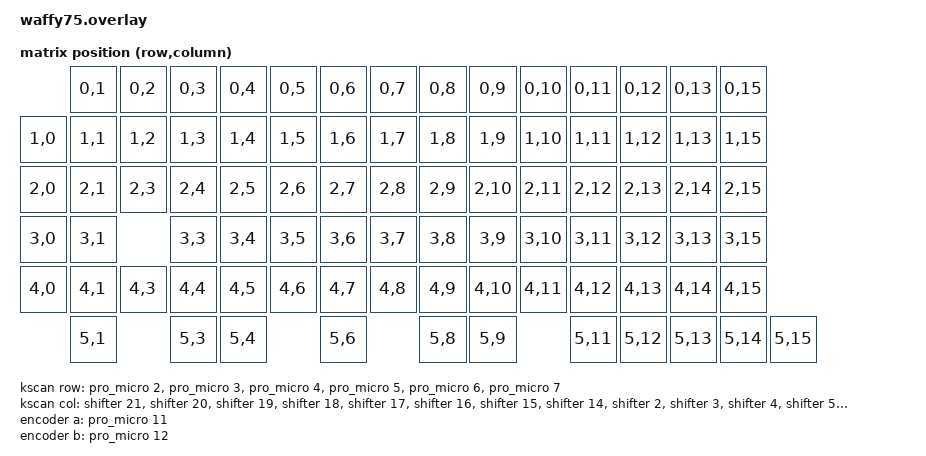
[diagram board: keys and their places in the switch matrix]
// This file was generated from a template. Edit it to match your keyboard.
// See https://zmk.dev/docs/development/hardware-integration/new-shield for more
// instructions.

#include <dt-bindings/zmk/matrix_transform.h>

#include "waffy75-layouts.dtsi"

&pro_micro_spi {
    status = "okay";
    cs-gpios = <&pro_micro 13 GPIO_ACTIVE_LOW>;
    shifter: 595@0 {
        compatible = "zmk,gpio-595";
        status = "okay";
        gpio-controller;
        spi-max-frequency = <200000>;
        reg = <0>;
        #gpio-cells = <2>;
        ngpios = <24>;
    };
};

/ {
    chosen {
        zmk,physical-layout = &default_layout;
    };

    kscan: kscan {
        // If the hardware does not use a switch matrix, change this to the
        // appropriate driver and update the properties below to match.
        // See https://zmk.dev/docs/config/kscan for supported key scan drivers.
        compatible = "zmk,kscan-gpio-matrix";
        // Set this to "col2row" or "row2col" to match the hardware. If using
        // "row2col", change the col-gpios to (GPIO_ACTIVE_HIGH | GPIO_PULL_DOWN)
        // and the row-gpios to GPIO_ACTIVE_HIGH.
        diode-direction = "col2row";
        wakeup-source;

        // Replace these comments with the GPIO pins in the matrix.
        // See https://zmk.dev/docs/development/hardware-integration/new-shield#shield-overlays
        col-gpios
            = <&shifter 21 GPIO_ACTIVE_HIGH>
            , <&shifter 20 GPIO_ACTIVE_HIGH>
            , <&shifter 19 GPIO_ACTIVE_HIGH>
            , <&shifter 18 GPIO_ACTIVE_HIGH>
            , <&shifter 17 GPIO_ACTIVE_HIGH>
            , <&shifter 16 GPIO_ACTIVE_HIGH>
            , <&shifter 15 GPIO_ACTIVE_HIGH>
            , <&shifter 14 GPIO_ACTIVE_HIGH>
            , <&shifter 2 GPIO_ACTIVE_HIGH>
            , <&shifter 3 GPIO_ACTIVE_HIGH>
            , <&shifter 4 GPIO_ACTIVE_HIGH>
            , <&shifter 5 GPIO_ACTIVE_HIGH>
            , <&shifter 6 GPIO_ACTIVE_HIGH>
            , <&shifter 7 GPIO_ACTIVE_HIGH>
            , <&shifter 8 GPIO_ACTIVE_HIGH>
            , <&shifter 9 GPIO_ACTIVE_HIGH>
            ;

        row-gpios
            = <&pro_micro 2 (GPIO_ACTIVE_HIGH | GPIO_PULL_DOWN)>
            , <&pro_micro 3 (GPIO_ACTIVE_HIGH | GPIO_PULL_DOWN)>
            , <&pro_micro 4 (GPIO_ACTIVE_HIGH | GPIO_PULL_DOWN)>
            , <&pro_micro 5 (GPIO_ACTIVE_HIGH | GPIO_PULL_DOWN)>
            , <&pro_micro 6 (GPIO_ACTIVE_HIGH | GPIO_PULL_DOWN)>
            , <&pro_micro 7 (GPIO_ACTIVE_HIGH | GPIO_PULL_DOWN)>
            ;
    };

    default_transform: default_transform {
        // See https://zmk.dev/docs/development/hardware-integration/new-shield#matrix-transform
        // for how to configure this
        compatible = "zmk,matrix-transform";
        columns = <16>;
        rows = <6>;

        map = <
                     RC(0, 1) RC(0, 2) RC(0, 3) RC(0, 4) RC(0, 5) RC(0, 6) RC(0, 7)     RC(0, 8) RC(0, 9) RC(0, 10) RC(0, 11) RC(0, 12) RC(0, 13)           RC(0, 15)
            RC(1, 0) RC(1, 1) RC(1, 2) RC(1, 3) RC(1, 4) RC(1, 5) RC(1, 6) RC(1, 7)     RC(1, 8) RC(1, 9) RC(1, 10) RC(1, 11) RC(1, 12) RC(1, 13)           RC(1, 15) 
            RC(2, 0) RC(2, 1)          RC(2, 3) RC(2, 4) RC(2, 5) RC(2, 6) RC(2, 7)     RC(2, 8) RC(2, 9) RC(2, 10) RC(2, 11) RC(2, 12) RC(2, 13) RC(2, 14) RC(2, 15)
            RC(3, 0) RC(3, 1)          RC(3, 3) RC(3, 4) RC(3, 5) RC(3, 6) RC(3, 7)     RC(3, 8) RC(3, 9) RC(3, 10) RC(3, 11) RC(3, 12) RC(3, 13)           RC(3, 15)
            RC(4, 0) RC(4, 1)          RC(4, 3) RC(4, 4) RC(4, 5) RC(4, 6) RC(4, 7)     RC(4, 8) RC(4, 9) RC(4, 10) RC(4, 11) RC(4, 12) RC(4, 13) RC(4, 14) RC(4, 15)
                     RC(5, 1)          RC(5, 3) RC(5, 4)          RC(5, 6)              RC(5, 8) RC(5, 9)           RC(5, 11) RC(5, 12) RC(5, 13) RC(5, 14) RC(5, 15)
        >; 
    };

    encoder: encoder {
        compatible = "alps,ec11";
        a-gpios = <&pro_micro 11 (GPIO_ACTIVE_HIGH | GPIO_PULL_UP)>;
        b-gpios = <&pro_micro 12 (GPIO_ACTIVE_HIGH | GPIO_PULL_UP)>;
        steps = <20>;
        status = "okay";
    };

    sensors: sensors {
        compatible = "zmk,keymap-sensors";
        sensors = <&encoder>;
        triggers-per-rotation = <20>;
    };
    
};


